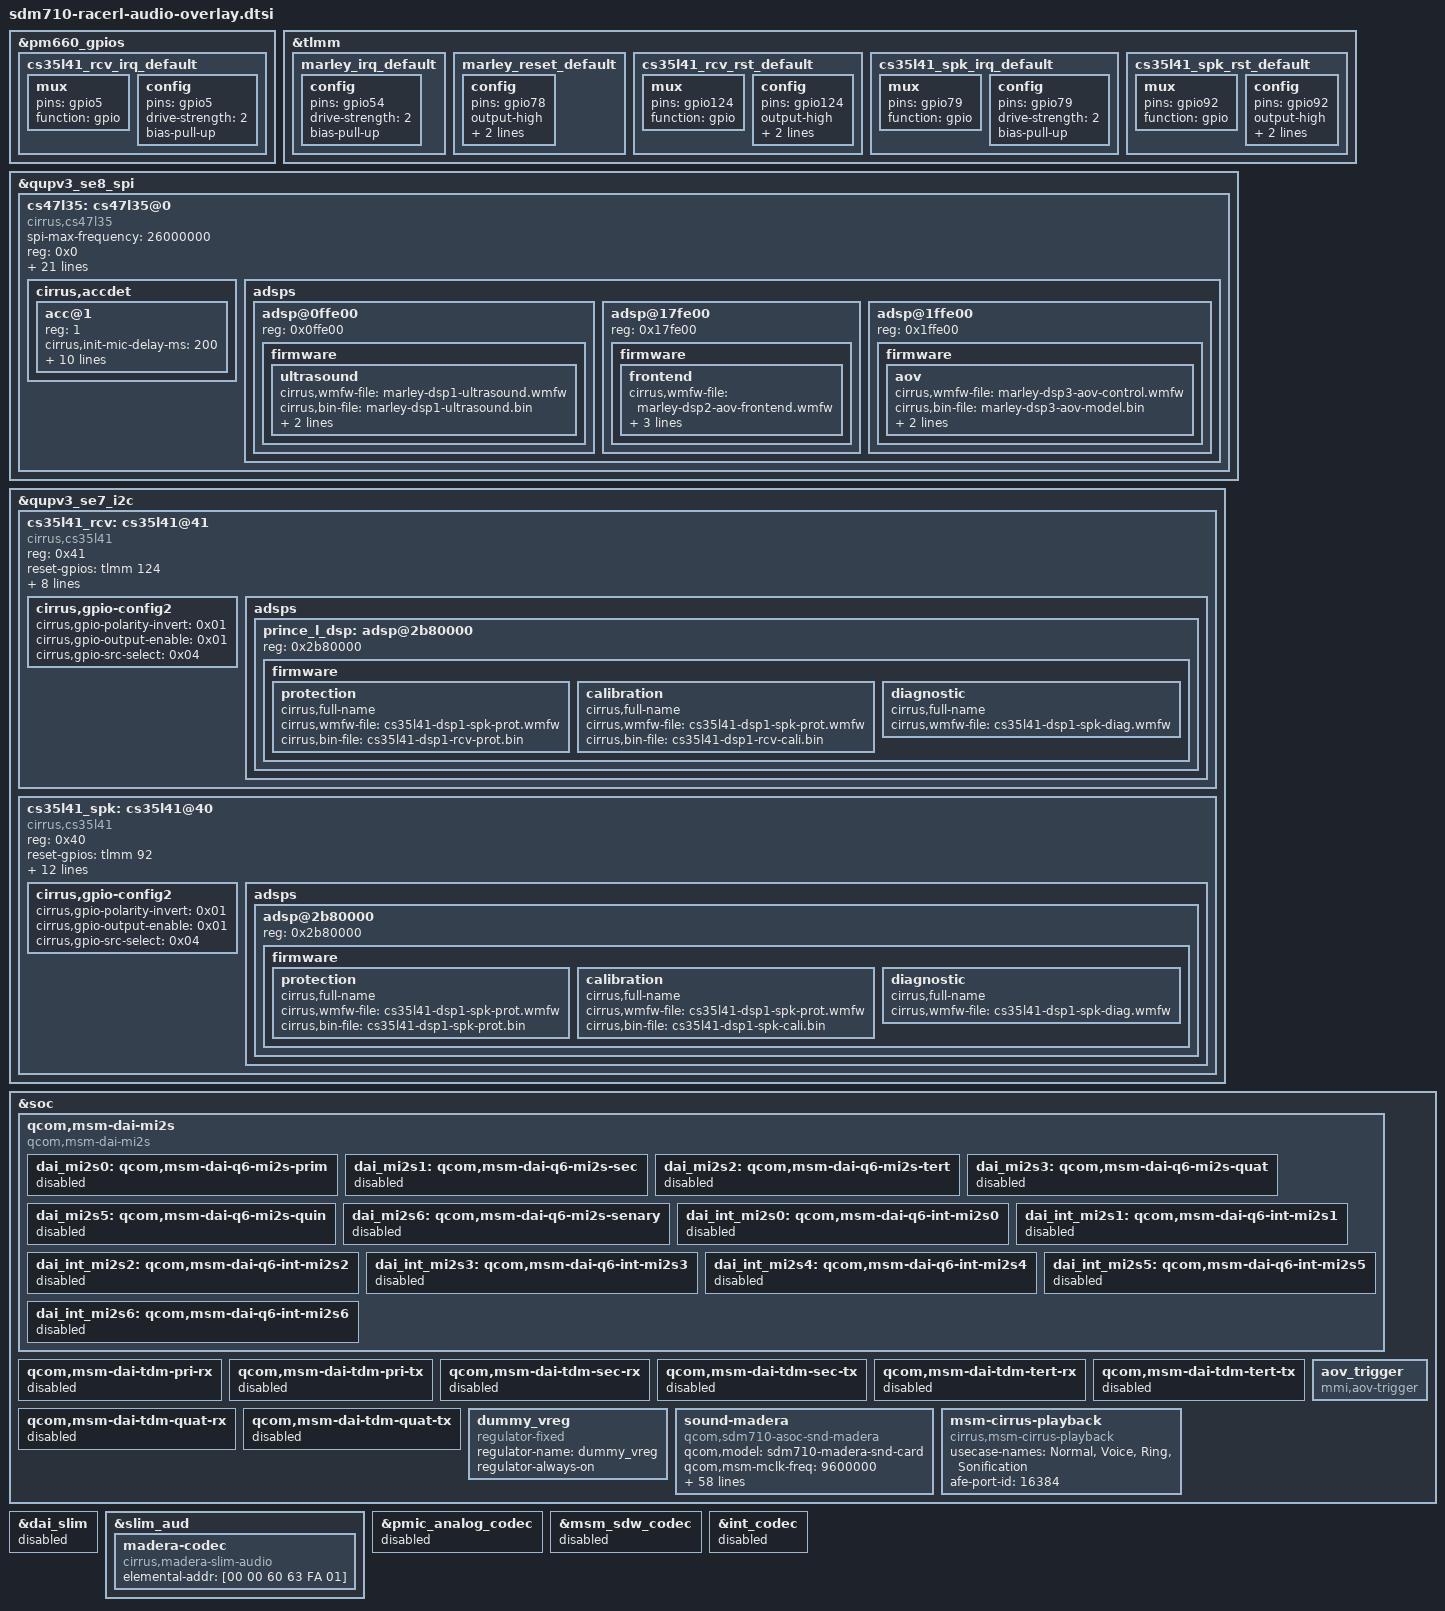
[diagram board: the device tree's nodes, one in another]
/* Copyright (c) 2019, The Linux Foundation. All rights reserved.
 *
 * This program is free software; you can redistribute it and/or modify
 * it under the terms of the GNU General Public License version 2 and
 * only version 2 as published by the Free Software Foundation.
 *
 * This program is distributed in the hope that it will be useful,
 * but WITHOUT ANY WARRANTY; without even the implied warranty of
 * MERCHANTABILITY or FITNESS FOR A PARTICULAR PURPOSE.  See the
 * GNU General Public License for more details.
 */

&pm660_gpios {
	cs35l41_rcv_irq_default: cs35l41_rcv_irq_default {
		mux {
			pins = "gpio5";
			function = "gpio";
		};
		config {
			pins = "gpio5";
			drive-strength = <2>;
			bias-pull-up;
		};
	};
};

&tlmm {
	marley_irq_default: marley_irq_default {
		config {
			pins = "gpio54";
			drive-strength = <2>;
			bias-pull-up;
		};
	};

	marley_reset_default: marley_reset_default {
		config {
			pins = "gpio78";
			output-high;
			bias-pull-up;
			drive-strength = <2>;
		};
	};

	cs35l41_rcv_rst_default: cs35l41_rcv_rst_default {
		mux {
			pins = "gpio124";
			function = "gpio";
		};
		config {
			pins = "gpio124";
			output-high;
			bias-pull-up;
			drive-strength = <2>;
		};
	};

	cs35l41_spk_irq_default: cs35l41_spk_irq_default {
		mux {
			pins = "gpio79";
			function = "gpio";
		};
		config {
			pins = "gpio79";
			drive-strength = <2>;
			bias-pull-up;
		};
	};

	cs35l41_spk_rst_default: cs35l41_spk_rst_default {
		mux {
			pins = "gpio92";
			function = "gpio";
		};
		config {
			pins = "gpio92";
			output-high;
			bias-pull-up;
			drive-strength = <2>;
		};
	};
};

&qupv3_se8_spi { /* Cirrus Audio */
	#address-cells = <1>;
	#size-cells = <0>;
	status = "ok";

	cs47l35: cs47l35@0{
		compatible = "cirrus,cs47l35";
		spi-max-frequency = <26000000>;
		reg = <0x0>;
		interrupt-parent = <&tlmm>;
		interrupts = <54 0>;
		interrupt-controller;
		#interrupt-cells = <2>;
		reset-gpios = <&tlmm 78 0>;
		pinctrl-names = "default";
		pinctrl-0 = <&marley_irq_default &marley_reset_default>;

		AVDD-supply = <&pm660_l14>;
		DBVDD1-supply = <&pm660_l14>;
		DBVDD2-supply = <&pm660_l14>;
		CPVDD-supply = <&pm660_l14>;
		CPVDD1-supply = <&pm660_l14>;
		CPVDD2-supply = <&pm660_l14>;
		DCVDD-supply = <&pm660_l13>;
		SPKVDD-supply = <&dummy_vreg>;

		gpio-controller;
		#gpio-cells = <2>;

		cirrus,gpio-defaults = <
			0x00002000 0x0000f000 /* AIF3TXDAT / GPIO1	*/
			0x00002000 0x0000f000 /* AIF3BCLK  / GPIO2	*/
			0x00000040 0x00000000 /* AIF3RXDAT / GPIO3	*/
			0x00002000 0x0000f000 /* AIF3LRCLK / GPIO4	*/
			0xffffffff 0xffffffff /* GPIO5 */
			0xffffffff 0xffffffff /* GPIO6 */
			0x00002000 0x0000f000 /* MIF1SDA   / GPIO7	*/
			0x00002000 0x0000f000 /* AIF1RXDAT / GPIO8	*/
			0x00002000 0x0000f000 /* AIF1BCLK  / GPIO9	*/
			0x00002000 0x0000f000 /* AIF1TXDAT / GPIO10 */
			0x00002000 0x0000f000 /* AIF1LRCLK / GPIO11 */
			0x00002000 0x0000f000 /* AIF2TXDAT / GPIO12 */
			0x00002000 0x0000f000 /* AIF2BCLK  / GPIO13 */
			0x00002000 0x0000f000 /* AIF2RXDAT / GPIO14 */
			0x00002000 0x0000f000 /* AIF2LRCLK / GPIO15 */
			0x00002000 0x0000f000 /* MIF1SCLK  / GPIO16 */
		>;

		cirrus,micbias1 = <2600 1 1 1 1 1 1 0>;
		cirrus,micbias2 = <2600 1 1 1 1 1 1 0>;
		cirrus,inmode = <
			0 0 0 1
			0 0 0 0
		>;
		cirrus,out-mono = <0 1 0 0 0 0>;

		cirrus,accdet {
			#address-cells = <1>;
			#size-cells = <0>;

			acc@1 {
				reg = <1>;

				cirrus,init-mic-delay-ms = <200>;
				cirrus,micd-manual-debounce = <3>;
				cirrus,micd-detect-debounce-ms = <600>;
				cirrus,micd-bias-start-time = <8>;
				cirrus,micd-rate = <6>;
				cirrus,micd-dbtime = <0x1>;
				cirrus,micd-ranges = <
					 100 226 /* HEADSETHOOK  */
					 150 582 /* VOICE_ASSIST */
					 295 115 /* VOLUME_UP	 */
					1257 114 /* VOLUME_DOWN  */
				>;
				cirrus,micd-configs = <
					0 1 2 0 0
				>;
				cirrus,micd-clamp-mode = <0x4>;
				cirrus,gpsw = <1 0>;
			};
		};

		adsps {
			#address-cells = <1>;
			#size-cells = <0>;
			adsp@0ffe00 {
				reg = <0x0ffe00>;
				firmware {
					ultrasound {
						cirrus,wmfw-file = "marley-dsp1-ultrasound.wmfw";
						cirrus,bin-file = "marley-dsp1-ultrasound.bin";
						cirrus,full-name;
						cirrus,compr-caps = <14 8 4 1 16000 96000>;
					};
				};
			};
			adsp@17fe00 {
				reg = <0x17fe00>;
				firmware {
					frontend {
						cirrus,wmfw-file = "marley-dsp2-aov-frontend.wmfw";
						cirrus,bin-file = "marley-dsp2-aov-vrgain.bin";
						cirrus,full-name;
						cirrus,compr-caps = <14 1 4 1 16000>;
					};
				};
			};
			adsp@1ffe00 {
				reg = <0x1ffe00>;
				firmware {
					aov {
						cirrus,wmfw-file = "marley-dsp3-aov-control.wmfw";
						cirrus,bin-file = "marley-dsp3-aov-model.bin";
						cirrus,full-name;
						cirrus,compr-caps = <14 1 4 1 16000>;
					};
				};
			};
		};
	};
};

&qupv3_se7_i2c {
	status = "ok";

	cs35l41_rcv:cs35l41@41 {
		status = "ok";
		compatible = "cirrus,cs35l41";
		reg = <0x41>;
		reset-gpios = <&tlmm 124 0>;

		VA-supply = <&pm660_l13>;
		VP-supply = <&pm660_l13>;

		pinctrl-names = "default";
		pinctrl-0 = <&cs35l41_rcv_rst_default>;

		cirrus,boost-ind-nanohenry = <1000>; /* 1uH */
		cirrus,boost-ctl-millivolt = <11000>;
		cirrus,boost-peak-milliamp = <4000>;
		cirrus,boost-cap-microfarad = <21>;
		cirrus,amp-gain-zc;

		cirrus,gpio-config2 {
			cirrus,gpio-polarity-invert = <0x01>;
			cirrus,gpio-output-enable = <0x01>;
			cirrus,gpio-src-select = <0x04>;
		};

		adsps {
			#address-cells = <1>;
			#size-cells = <0>;
			prince_l_dsp: adsp@2b80000 {
				reg = <0x2b80000>;
				firmware {
					protection {
						cirrus,full-name;
						cirrus,wmfw-file = "cs35l41-dsp1-spk-prot.wmfw";
						cirrus,bin-file = "cs35l41-dsp1-rcv-prot.bin";
					};
					calibration {
						cirrus,full-name;
						cirrus,wmfw-file = "cs35l41-dsp1-spk-prot.wmfw";
						cirrus,bin-file = "cs35l41-dsp1-rcv-cali.bin";
					};
					diagnostic {
						cirrus,full-name;
						cirrus,wmfw-file = "cs35l41-dsp1-spk-diag.wmfw";
					};
				};
			};
		};
	};

	cs35l41_spk:cs35l41@40 {
		status = "ok";
		compatible = "cirrus,cs35l41";
		reg = <0x40>;
		reset-gpios = <&tlmm 92 0>;
		interrupts = <79 0>;
		interrupt-parent = <&tlmm>;
		interrupt-names = "prince_spk_irq";

		VA-supply = <&pm660_l13>;
		VP-supply = <&pm660_l13>;

		pinctrl-names = "default";
		pinctrl-0 = <&cs35l41_spk_rst_default &cs35l41_spk_irq_default>;

		cirrus,right-channel-amp;
		cirrus,boost-ind-nanohenry = <1000>; /* 1uH */
		cirrus,boost-ctl-millivolt = <11000>;
		cirrus,boost-peak-milliamp = <4000>;
		cirrus,boost-cap-microfarad = <21>;
		cirrus,amp-gain-zc;

		cirrus,gpio-config2 {
			cirrus,gpio-polarity-invert = <0x01>;
			cirrus,gpio-output-enable = <0x01>;
			cirrus,gpio-src-select = <0x04>;
		};

		adsps {
			#address-cells = <1>;
			#size-cells = <0>;
			adsp@2b80000 {
				reg = <0x2b80000>;
				firmware {
					protection {
						cirrus,full-name;
						cirrus,wmfw-file = "cs35l41-dsp1-spk-prot.wmfw";
						cirrus,bin-file = "cs35l41-dsp1-spk-prot.bin";
					};
					calibration {
						cirrus,full-name;
						cirrus,wmfw-file = "cs35l41-dsp1-spk-prot.wmfw";
						cirrus,bin-file = "cs35l41-dsp1-spk-cali.bin";
					};
					diagnostic {
						cirrus,full-name;
						cirrus,wmfw-file = "cs35l41-dsp1-spk-diag.wmfw";
					};
				};
			};
		};
	};
};

&soc {
	qcom,msm-dai-mi2s {
		compatible = "qcom,msm-dai-mi2s";
		dai_mi2s0: qcom,msm-dai-q6-mi2s-prim {
			status = "disabled";
		};

		dai_mi2s1: qcom,msm-dai-q6-mi2s-sec {
			status = "disabled";
		};

		dai_mi2s2: qcom,msm-dai-q6-mi2s-tert {
			status = "disabled";
		};

		dai_mi2s3: qcom,msm-dai-q6-mi2s-quat {
			status = "disabled";
		};

		dai_mi2s5: qcom,msm-dai-q6-mi2s-quin {
			status = "disabled";
		};

		dai_mi2s6: qcom,msm-dai-q6-mi2s-senary {
			status = "disabled";
		};

		dai_int_mi2s0: qcom,msm-dai-q6-int-mi2s0 {
			status = "disabled";
		};

		dai_int_mi2s1: qcom,msm-dai-q6-int-mi2s1 {
			status = "disabled";
		};

		dai_int_mi2s2: qcom,msm-dai-q6-int-mi2s2 {
			status = "disabled";
		};

		dai_int_mi2s3: qcom,msm-dai-q6-int-mi2s3 {
			status = "disabled";
		};

		dai_int_mi2s4: qcom,msm-dai-q6-int-mi2s4 {
			status = "disabled";
		};

		dai_int_mi2s5: qcom,msm-dai-q6-int-mi2s5 {
			status = "disabled";
		};

		dai_int_mi2s6: qcom,msm-dai-q6-int-mi2s6 {
			status = "disabled";
		};
	};

	qcom,msm-dai-tdm-pri-rx {
		status = "disabled";
	};

	qcom,msm-dai-tdm-pri-tx {
		status = "disabled";
	};

	qcom,msm-dai-tdm-sec-rx {
		status = "disabled";
	};

	qcom,msm-dai-tdm-sec-tx {
		status = "disabled";
	};

	qcom,msm-dai-tdm-tert-rx {
		status = "disabled";
	};

	qcom,msm-dai-tdm-tert-tx {
		status = "disabled";
	};

	qcom,msm-dai-tdm-quat-rx {
		status = "disabled";
	};

	qcom,msm-dai-tdm-quat-tx {
		status = "disabled";
	};

	dummy_vreg: dummy_vreg {
		compatible = "regulator-fixed";
		status = "ok";
		regulator-name = "dummy_vreg";
		regulator-always-on;
	};

	aov_trigger {
		status = "ok";
		compatible = "mmi,aov-trigger";
	};

	sound-madera {
		status = "ok";
		compatible = "qcom,sdm710-asoc-snd-madera";
		qcom,model = "sdm710-madera-snd-card";
		qcom,msm-mclk-freq = <9600000>;
		qcom,ext-disp-audio-rx;
		qcom,wcn-btfm;

		asoc-platform = <&pcm0>, <&pcm1>, <&pcm2>, <&voip>, <&voice>,
				<&loopback>, <&compress>, <&hostless>,
				<&afe>, <&lsm>, <&routing>, <&compr>,
				<&pcm_noirq>, <&cs47l35>;
		asoc-platform-names = "msm-pcm-dsp.0", "msm-pcm-dsp.1",
				"msm-pcm-dsp.2", "msm-voip-dsp",
				"msm-pcm-voice", "msm-pcm-loopback",
				"msm-compress-dsp", "msm-pcm-hostless",
				"msm-pcm-afe", "msm-lsm-client",
				"msm-pcm-routing", "msm-compr-dsp",
				"msm-pcm-dsp-noirq", "cs47l35-codec";
		asoc-cpu = <&dai_hdmi>, <&dai_dp>,
				<&dai_mi2s0>, <&dai_mi2s1>,
				<&dai_mi2s2>, <&dai_mi2s3>,
				<&dai_pri_auxpcm>, <&dai_sec_auxpcm>,
				<&dai_tert_auxpcm>, <&dai_quat_auxpcm>,
				<&sb_0_rx>, <&sb_0_tx>, <&sb_1_rx>, <&sb_1_tx>,
				<&sb_2_rx>, <&sb_2_tx>, <&sb_3_rx>, <&sb_3_tx>,
				<&sb_4_rx>, <&sb_4_tx>, <&sb_5_tx>,
				<&afe_pcm_rx>, <&afe_pcm_tx>, <&afe_proxy_rx>,
				<&afe_proxy_tx>, <&incall_record_rx>,
				<&incall_record_tx>, <&incall_music_rx>,
				<&incall_music_2_rx>, <&sb_5_rx>, <&sb_6_rx>,
				<&sb_7_rx>, <&sb_7_tx>, <&sb_8_tx>,
				<&usb_audio_rx>, <&usb_audio_tx>,
				<&dai_pri_tdm_rx_0>, <&dai_pri_tdm_tx_0>,
				<&dai_sec_tdm_rx_0>, <&dai_sec_tdm_tx_0>,
				<&dai_tert_tdm_rx_0>, <&dai_tert_tdm_tx_0>,
				<&dai_quat_tdm_rx_0>, <&dai_quat_tdm_tx_0>;
		asoc-cpu-names = "msm-dai-q6-hdmi.8",  "msm-dai-q6-dp.24608",
				"msm-dai-q6-mi2s.0", "msm-dai-q6-mi2s.1",
				"msm-dai-q6-mi2s.2", "msm-dai-q6-mi2s.3",
				"msm-dai-q6-auxpcm.1", "msm-dai-q6-auxpcm.2",
				"msm-dai-q6-auxpcm.3", "msm-dai-q6-auxpcm.4",
				"msm-dai-q6-dev.16384", "msm-dai-q6-dev.16385",
				"msm-dai-q6-dev.16386", "msm-dai-q6-dev.16387",
				"msm-dai-q6-dev.16388", "msm-dai-q6-dev.16389",
				"msm-dai-q6-dev.16390", "msm-dai-q6-dev.16391",
				"msm-dai-q6-dev.16392", "msm-dai-q6-dev.16393",
				"msm-dai-q6-dev.16395", "msm-dai-q6-dev.224",
				"msm-dai-q6-dev.225", "msm-dai-q6-dev.241",
				"msm-dai-q6-dev.240", "msm-dai-q6-dev.32771",
				"msm-dai-q6-dev.32772", "msm-dai-q6-dev.32773",
				"msm-dai-q6-dev.32770", "msm-dai-q6-dev.16394",
				"msm-dai-q6-dev.16396", "msm-dai-q6-dev.16398",
				"msm-dai-q6-dev.16399", "msm-dai-q6-dev.16401",
				"msm-dai-q6-dev.28672", "msm-dai-q6-dev.28673",
				"msm-dai-q6-tdm.36864", "msm-dai-q6-tdm.36865",
				"msm-dai-q6-tdm.36880", "msm-dai-q6-tdm.36881",
				"msm-dai-q6-tdm.36896", "msm-dai-q6-tdm.36897",
				"msm-dai-q6-tdm.36912", "msm-dai-q6-tdm.36913";

		asoc-codec = <&stub_codec>, <&ext_disp_audio_codec>,
					<&cs35l41_rcv>, <&cs35l41_spk>;
		asoc-codec-names = "msm-stub-codec.1",
				   "msm-ext-disp-audio-codec-rx",
				   "cs35l41-rcv", "cs35l41-spk";
		qcom,audio-routing =
			"IN1AL", "MICBIAS2A",
			"IN2L",  "MICBIAS2B",
			"IN1BR", "MICBIAS1B";
	};

	msm-cirrus-playback {
		compatible = "cirrus,msm-cirrus-playback";
		usecase-names = "Normal", "Voice", "Ring", "Sonification";
		afe-port-id = <16384>;
	};
};

&dai_slim {
	status = "disabled";
};

&slim_aud {
	status = "okay";
	madera-codec {
		compatible = "cirrus,madera-slim-audio";
		elemental-addr = [00 00 60 63 FA 01];
	};
};

&pmic_analog_codec {
	status = "disabled";
};

&msm_sdw_codec {
	status = "disabled";
};

&int_codec {
	status = "disabled";
};

